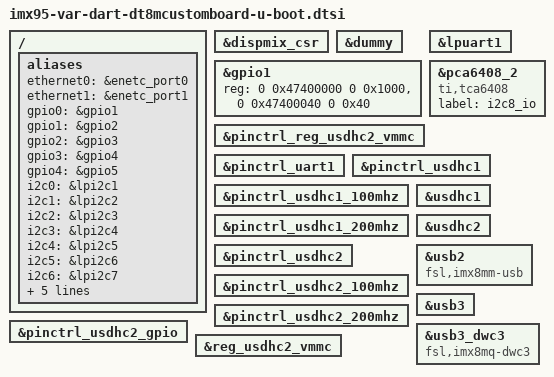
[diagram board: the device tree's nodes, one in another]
// SPDX-License-Identifier: GPL-2.0+
/*
 * Copyright 2023 NXP
 * Copyright 2024-2025 Variscite Ltd.
 */

/ {
	aliases {
		ethernet0 = &enetc_port0;
		ethernet1 = &enetc_port1;
		gpio0 = &gpio1;
		gpio1 = &gpio2;
		gpio2 = &gpio3;
		gpio3 = &gpio4;
		gpio4 = &gpio5;
		i2c0 = &lpi2c1;
		i2c1 = &lpi2c2;
		i2c2 = &lpi2c3;
		i2c3 = &lpi2c4;
		i2c4 = &lpi2c5;
		i2c5 = &lpi2c6;
		i2c6 = &lpi2c7;
		i2c7 = &lpi2c8;
		mmc0 = &usdhc1;
		mmc1 = &usdhc2;
		usb0 = &usb3_dwc3;
		usb1 = &usb2;
	};
};

&dispmix_csr {
	/delete-property/ assigned-clocks;
	/delete-property/ assigned-clock-rates;
	/delete-property/ assigned-clock-parents;
};

&dummy {
	bootph-all;
	bootph-pre-ram;
};

&gpio1 {
	reg = <0 0x47400000 0 0x1000>, <0 0x47400040 0 0x40>;
};

&lpuart1 {
	bootph-pre-ram;
};

&pca6408_2 {
	compatible = "ti,tca6408";
	label = "i2c8_io";
};

&pinctrl_reg_usdhc2_vmmc {
	bootph-pre-ram;
};

&pinctrl_uart1 {
	bootph-pre-ram;
};

&pinctrl_usdhc1 {
	bootph-pre-ram;
};

&pinctrl_usdhc1_100mhz {
	bootph-pre-ram;
};

&pinctrl_usdhc1_200mhz {
	bootph-pre-ram;
};

&pinctrl_usdhc2 {
	bootph-pre-ram;
};

&pinctrl_usdhc2_100mhz {
	bootph-pre-ram;
};

&pinctrl_usdhc2_200mhz {
	bootph-pre-ram;
};

&pinctrl_usdhc2_gpio {
	bootph-pre-ram;
};

&reg_usdhc2_vmmc {
	bootph-pre-ram;
};

&usdhc1 {
	bootph-pre-ram;
};

&usdhc2 {
	bootph-pre-ram;
};

&usb2 {
	compatible = "fsl,imx8mm-usb", "fsl,imx7d-usb";
	/delete-property/power-domains;
};

&usb3 {
	/delete-property/power-domains;
};

&usb3_dwc3 {
	compatible = "fsl,imx8mq-dwc3", "snps,dwc3";
};
